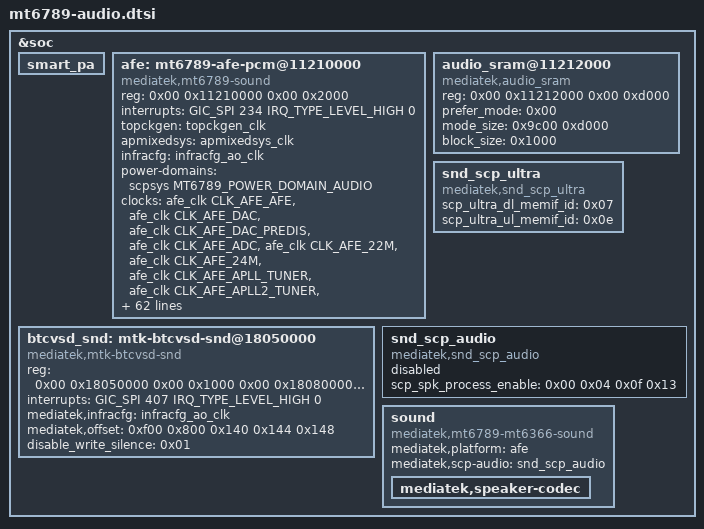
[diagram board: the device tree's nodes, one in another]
// SPDX-License-Identifier: (GPL-2.0 OR MIT)
/* MT6789 audio blocks -- split out of the SoC node, one subsystem per file. */

&soc {
	smart_pa: smart_pa {
	};

	afe: mt6789-afe-pcm@11210000 {
		compatible = "mediatek,mt6789-sound";
		reg = <0x00 0x11210000 0x00 0x2000>;
		interrupts = <GIC_SPI 234 IRQ_TYPE_LEVEL_HIGH 0>;
		topckgen = <&topckgen_clk>;
		apmixedsys = <&apmixedsys_clk>;
		infracfg = <&infracfg_ao_clk>;
		power-domains = <&scpsys MT6789_POWER_DOMAIN_AUDIO>;
		clocks = <&afe_clk CLK_AFE_AFE &afe_clk CLK_AFE_DAC &afe_clk CLK_AFE_DAC_PREDIS &afe_clk CLK_AFE_ADC &afe_clk CLK_AFE_22M &afe_clk CLK_AFE_24M &afe_clk CLK_AFE_APLL_TUNER &afe_clk CLK_AFE_APLL2_TUNER &afe_clk CLK_AFE_TML &afe_clk CLK_AFE_NLE &afe_clk CLK_AFE_DAC_HIRES &afe_clk CLK_AFE_ADC_HIRES &afe_clk CLK_AFE_ADC_HIRES_TML &afe_clk CLK_AFE_I2S1_BCLK &afe_clk CLK_AFE_I2S2_BCLK &afe_clk CLK_AFE_I2S3_BCLK &afe_clk CLK_AFE_I2S4_BCLK &afe_clk CLK_AFE_GENERAL3_ASRC &afe_clk CLK_AFE_CONNSYS_I2S_ASRC &afe_clk CLK_AFE_GENERAL1_ASRC &afe_clk CLK_AFE_GENERAL2_ASRC &infracfg_ao_clk CLK_IFRAO_AUDIO &infracfg_ao_clk CLK_IFRAO_AUDIO_26M_BCLK &apmixedsys_clk CLK_APMIXED_APLL1 &apmixedsys_clk CLK_APMIXED_APLL2 &topckgen_clk CLK_TOP_AUDIO_SEL &topckgen_clk CLK_TOP_AUD_INTBUS_SEL &topckgen_clk CLK_TOP_MAINPLL_D4_D4 &topckgen_clk CLK_TOP_AUD_1_SEL &topckgen_clk CLK_TOP_APLL1 &topckgen_clk CLK_TOP_AUD_2_SEL &topckgen_clk CLK_TOP_APLL2 &topckgen_clk CLK_TOP_AUD_ENGEN1_SEL &topckgen_clk CLK_TOP_APLL1_D4 &topckgen_clk CLK_TOP_APLL1_D8 &topckgen_clk CLK_TOP_AUD_ENGEN2_SEL &topckgen_clk CLK_TOP_APLL2_D4 &topckgen_clk CLK_TOP_APLL2_D8 &topckgen_clk CLK_TOP_APLL_I2S0_MCK_SEL &topckgen_clk CLK_TOP_APLL_I2S1_MCK_SEL &topckgen_clk CLK_TOP_APLL_I2S2_MCK_SEL &topckgen_clk CLK_TOP_APLL_I2S3_MCK_SEL &topckgen_clk CLK_TOP_APLL_I2S4_MCK_SEL &topckgen_clk CLK_TOP_APLL_I2S5_MCK_SEL &topckgen_clk CLK_TOP_APLL12_CK_DIV0 &topckgen_clk CLK_TOP_APLL12_CK_DIV1 &topckgen_clk CLK_TOP_APLL12_CK_DIV2 &topckgen_clk CLK_TOP_APLL12_CK_DIV3 &topckgen_clk CLK_TOP_APLL12_CK_DIV4 &topckgen_clk CLK_TOP_APLL12_CK_DIVB &topckgen_clk CLK_TOP_APLL12_CK_DIV5 &topckgen_clk CLK_TOP_AUDIO_H_SEL &topckgen_clk CLK_TOP_TCK_26M_MX9>;
		clock-names = "aud_afe_clk", "aud_dac_clk", "aud_dac_predis_clk", "aud_adc_clk", "aud_apll22m_clk", "aud_apll24m_clk", "aud_apll1_tuner_clk", "aud_apll2_tuner_clk", "aud_tml_clk", "aud_nle", "aud_dac_hires_clk", "aud_adc_hires_clk", "aud_adc_hires_tml", "aud_i2s1_bclk", "aud_i2s2_bclk", "aud_i2s3_bclk", "aud_i2s4_bclk", "aud_general3_asrc", "aud_connsys_i2s_asrc", "aud_general1_asrc", "aud_general2_asrc", "aud_infra_clk", "aud_infra_26m_clk", "aud_clk_apmixed_apll1", "aud_clk_apmixed_apll2", "top_mux_audio", "top_mux_audio_int", "top_mainpll_d4_d4", "top_mux_aud_1", "top_apll1_ck", "top_mux_aud_2", "top_apll2_ck", "top_mux_aud_eng1", "top_apll1_d4", "top_apll1_d8", "top_mux_aud_eng2", "top_apll2_d4", "top_apll2_d8", "top_i2s0_m_sel", "top_i2s1_m_sel", "top_i2s2_m_sel", "top_i2s3_m_sel", "top_i2s4_m_sel", "top_i2s5_m_sel", "top_apll12_div0", "top_apll12_div1", "top_apll12_div2", "top_apll12_div3", "top_apll12_div4", "top_apll12_divb", "top_apll12_div5", "top_mux_audio_h", "top_clk26m_clk";
		pinctrl-names = "aud_clk_mosi_off", "aud_clk_mosi_on", "aud_clk_miso_off", "aud_clk_miso_on", "aud_dat_mosi_off", "aud_dat_mosi_on", "aud_dat_miso0_off", "aud_dat_miso0_on", "aud_dat_miso1_off", "aud_dat_miso1_on", "aud_gpio_i2s0_off", "aud_gpio_i2s0_on", "aud_gpio_i2s3_off", "aud_gpio_i2s3_on", "vow_dat_miso_off", "vow_dat_miso_on", "vow_clk_miso_off", "vow_clk_miso_on";
		pinctrl-0 = <&aud_clk_mosi_off>;
		pinctrl-1 = <&aud_clk_mosi_on>;
		pinctrl-2 = <&aud_clk_miso_off>;
		pinctrl-3 = <&aud_clk_miso_on>;
		pinctrl-4 = <&aud_dat_mosi_off>;
		pinctrl-5 = <&aud_dat_mosi_on>;
		pinctrl-6 = <&aud_dat_miso0_off>;
		pinctrl-7 = <&aud_dat_miso0_on>;
		pinctrl-8 = <&aud_dat_miso1_off>;
		pinctrl-9 = <&aud_dat_miso1_on>;
		pinctrl-10 = <&aud_gpio_i2s0_off>;
		pinctrl-11 = <&aud_gpio_i2s0_on>;
		pinctrl-12 = <&aud_gpio_i2s3_off>;
		pinctrl-13 = <&aud_gpio_i2s3_on>;
		pinctrl-14 = <&vow_dat_miso_off>;
		pinctrl-15 = <&vow_dat_miso_on>;
		pinctrl-16 = <&vow_clk_miso_off>;
		pinctrl-17 = <&vow_clk_miso_on>;
	};

	audio_sram@11212000 {
		compatible = "mediatek,audio_sram";
		reg = <0x00 0x11212000 0x00 0xd000>;
		prefer_mode = <0x00>;
		mode_size = <0x9c00 0xd000>;
		block_size = <0x1000>;
	};

	btcvsd_snd: mtk-btcvsd-snd@18050000 {
		compatible = "mediatek,mtk-btcvsd-snd";
		reg = <0x00 0x18050000 0x00 0x1000 0x00 0x18080000 0x00 0x10000>;
		interrupts = <GIC_SPI 407 IRQ_TYPE_LEVEL_HIGH 0>;
		mediatek,infracfg = <&infracfg_ao_clk>;
		mediatek,offset = <0xf00 0x800 0x140 0x144 0x148>;
		disable_write_silence = <0x01>;
	};

	snd_scp_ultra: snd_scp_ultra {
		compatible = "mediatek,snd_scp_ultra";
		scp_ultra_dl_memif_id = <0x07>;
		scp_ultra_ul_memif_id = <0x0e>;
	};

	snd_scp_audio: snd_scp_audio {
		compatible = "mediatek,snd_scp_audio";
		status = "disabled";
		scp_spk_process_enable = <0x00 0x04 0x0f 0x13>;
	};

	sound: sound {
		compatible = "mediatek,mt6789-mt6366-sound";
		mediatek,platform = <&afe>;
		mediatek,scp-audio = <&snd_scp_audio>;

		mediatek,speaker-codec {
		};
	};

};
